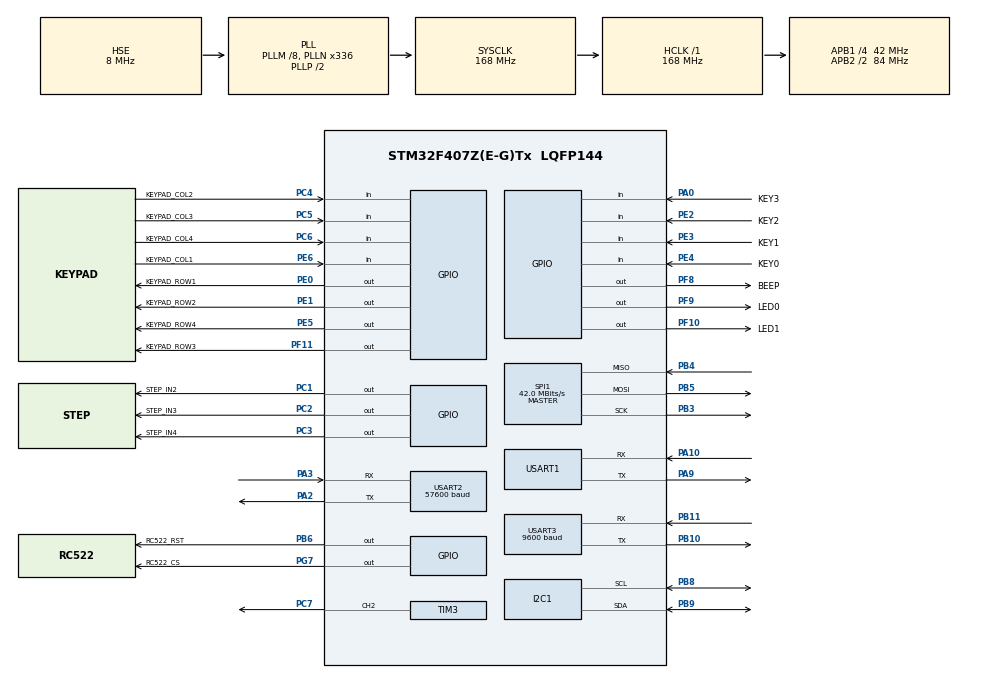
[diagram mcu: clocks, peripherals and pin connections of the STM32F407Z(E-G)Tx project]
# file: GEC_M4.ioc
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FREERTOS.Tasks01=defaultTask,24,128,StartDefaultTask,Default,NULL,Dynamic,NULL,NULL
Mcu.Family=STM32F4
Mcu.Name=STM32F407Z(E-G)Tx
Mcu.Package=LQFP144
NVIC.PriorityGroup=NVIC_PRIORITYGROUP_4
NVIC.TIM1_UP_TIM10_IRQn=true\:0\:0\:false\:false\:true\:false\:false\:true
NVIC.TimeBase=TIM1_UP_TIM10_IRQn
NVIC.TimeBaseIP=TIM1
NVIC.USART1_IRQn=true\:5\:0\:true\:false\:true\:true\:true\:true
NVIC.USART2_IRQn=true\:5\:0\:true\:false\:true\:true\:true\:true
NVIC.USART3_IRQn=true\:5\:0\:true\:false\:true\:true\:true\:true
PA0-WKUP.GPIO_Label=KEY3
PA0-WKUP.GPIO_Pull=GPIO_NOPULL
PA0-WKUP.Signal=GPIO_Input
PA10.Mode=Asynchronous
PA10.Signal=USART1_RX
PA13.Mode=Serial_Wire
PA13.Signal=SYS_JTMS-SWDIO
PA14.Mode=Serial_Wire
PA14.Signal=SYS_JTCK-SWCLK
PA2.Mode=Asynchronous
PA2.Signal=USART2_TX
PA3.Mode=Asynchronous
PA3.Signal=USART2_RX
PA9.Mode=Asynchronous
PA9.Signal=USART1_TX
PB10.Mode=Asynchronous
PB10.Signal=USART3_TX
PB11.Mode=Asynchronous
PB11.Signal=USART3_RX
PC7.Signal=S_TIM3_CH2
PF11.GPIO_Label=KEYPAD_ROW3
PF11.Signal=GPIO_Output
PG7.GPIO_Label=RC522_CS
PG7.Signal=GPIO_Output
PB3.Mode=Full_Duplex_Master
PB3.Signal=SPI1_SCK
PB4.Mode=Full_Duplex_Master
PB4.Signal=SPI1_MISO
PB5.Mode=Full_Duplex_Master
PB5.Signal=SPI1_MOSI
PB6.GPIO_Label=RC522_RST
PB6.Signal=GPIO_Output
PB8.Mode=I2C
PB8.Signal=I2C1_SCL
PB9.Mode=I2C
PB9.Signal=I2C1_SDA
PC1.GPIO_Label=STEP_IN2
PC1.GPIO_Speed=GPIO_SPEED_FREQ_VERY_HIGH
PC1.Signal=GPIO_Output
PC14-OSC32_IN.Mode=LSE-External-Oscillator
PC14-OSC32_IN.Signal=RCC_OSC32_IN
PC15-OSC32_OUT.Mode=LSE-External-Oscillator
PC15-OSC32_OUT.Signal=RCC_OSC32_OUT
PC2.GPIO_Label=STEP_IN3
PC2.GPIO_Speed=GPIO_SPEED_FREQ_VERY_HIGH
PC2.Signal=GPIO_Output
PC3.GPIO_Label=STEP_IN4
PC3.GPIO_Speed=GPIO_SPEED_FREQ_VERY_HIGH
PC3.Signal=GPIO_Output
PC4.GPIO_Label=KEYPAD_COL2
PC4.GPIO_Pull=GPIO_PULLUP
PC4.Signal=GPIO_Input
PC5.GPIO_Label=KEYPAD_COL3
PC5.GPIO_Pull=GPIO_PULLUP
PC5.Signal=GPIO_Input
PC6.GPIO_Label=KEYPAD_COL4
PC6.GPIO_Pull=GPIO_PULLUP
PC6.Signal=GPIO_Input
PE0.GPIO_Label=KEYPAD_ROW1
PE0.GPIO_Speed=GPIO_SPEED_FREQ_VERY_HIGH
PE0.Signal=GPIO_Output
PE1.GPIO_Label=KEYPAD_ROW2
PE1.GPIO_Speed=GPIO_SPEED_FREQ_VERY_HIGH
PE1.Signal=GPIO_Output
PE2.GPIO_Label=KEY2
PE2.GPIO_Pull=GPIO_NOPULL
PE2.Signal=GPIO_Input
PE3.GPIO_Label=KEY1
PE3.GPIO_Pull=GPIO_NOPULL
PE3.Signal=GPIO_Input
PE4.GPIO_Label=KEY0
PE4.GPIO_Pull=GPIO_NOPULL
PE4.Signal=GPIO_Input
PE5.GPIO_Label=KEYPAD_ROW4
PE5.GPIO_Speed=GPIO_SPEED_FREQ_VERY_HIGH
PE5.Signal=GPIO_Output
PE6.GPIO_Label=KEYPAD_COL1
PE6.GPIO_Pull=GPIO_PULLUP
PE6.Signal=GPIO_Input
PF10.GPIO_Label=LED1
PF10.GPIO_Speed=GPIO_SPEED_FREQ_VERY_HIGH
PF10.Signal=GPIO_Output
PF8.GPIO_Label=BEEP
PF8.GPIO_Speed=GPIO_SPEED_FREQ_VERY_HIGH
PF8.Signal=GPIO_Output
PF9.GPIO_Label=LED0
PF9.GPIO_Speed=GPIO_SPEED_FREQ_VERY_HIGH
PF9.Signal=GPIO_Output
PH0-OSC_IN.Mode=HSE-External-Oscillator
PH0-OSC_IN.Signal=RCC_OSC_IN
PH1-OSC_OUT.Mode=HSE-External-Oscillator
PH1-OSC_OUT.Signal=RCC_OSC_OUT
ProjectManager.HeapSize=0x200
ProjectManager.StackSize=0x400
ProjectManager.TargetToolchain=MDK-ARM V5.27
RCC.48MHZClocksFreq_Value=84000000
RCC.AHBFreq_Value=168000000
RCC.APB1CLKDivider=RCC_HCLK_DIV4
RCC.APB1Freq_Value=42000000
RCC.APB1TimFreq_Value=84000000
RCC.APB2CLKDivider=RCC_HCLK_DIV2
RCC.APB2Freq_Value=84000000
RCC.APB2TimFreq_Value=168000000
RCC.CortexFreq_Value=168000000
RCC.HCLKFreq_Value=168000000
RCC.HSE_VALUE=8000000
RCC.HSI_VALUE=16000000
RCC.PLLM=8
RCC.PLLN=336
RCC.PLLSourceVirtual=RCC_PLLSOURCE_HSE
RCC.SYSCLKFreq_VALUE=168000000
RCC.SYSCLKSource=RCC_SYSCLKSOURCE_PLLCLK
RCC.VCOOutputFreq_Value=336000000
SH.S_TIM3_CH2.0=TIM3_CH2,PWM Generation2 CH2
SPI1.CalculateBaudRate=42.0 MBits/s
SPI1.Direction=SPI_DIRECTION_2LINES
SPI1.Mode=SPI_MODE_MASTER
SPI1.VirtualType=VM_MASTER
TIM3.Channel-PWM\ Generation2\ CH2=TIM_CHANNEL_2
TIM3.Period=19999
TIM3.Prescaler=83
USART1.VirtualMode=VM_ASYNC
USART2.BaudRate=57600
USART2.VirtualMode=VM_ASYNC
USART3.BaudRate=9600
USART3.VirtualMode=VM_ASYNC
VP_FREERTOS_VS_CMSIS_V2.Mode=CMSIS_V2
VP_SYS_VS_tim1.Mode=TIM1
VP_TIM3_VS_ClockSourceINT.Mode=Internal
board=custom

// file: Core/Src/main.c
/* USER CODE BEGIN Header */
/**
  ******************************************************************************
  * @file           : main.c
  * @brief          : Main program body
  ******************************************************************************
  * @attention
  *
  * <h2><center>&copy; Copyright (c) 2026 STMicroelectronics.
  * All rights reserved.</center></h2>
  *
  * This software component is licensed by ST under Ultimate Liberty license
  * SLA0044, the "License"; You may not use this file except in compliance with
  * the License. You may obtain a copy of the License at:
  *                             www.st.com/SLA0044
  *
  ******************************************************************************
  */
/* USER CODE END Header */
#include "main.h"
#include "cmsis_os.h"
#include "i2c.h"
#include "spi.h"
#include "tim.h"
#include "usart.h"
#include "gpio.h"

/* USER CODE BEGIN Includes */
#include "app_auth.h"
/* USER CODE END Includes */

void SystemClock_Config(void);
void MX_FREERTOS_Init(void);

int main(void)
{

  /* MCU Configuration--------------------------------------------------------*/

  /* Reset of all peripherals, Initializes the Flash interface and the Systick. */
  HAL_Init();

  /* Configure the system clock */
  SystemClock_Config();

  /* Initialize all configured peripherals */
  MX_GPIO_Init();            /* 通用 GPIO：4x4 矩阵键盘行/列引脚、LED 等 */
  MX_USART1_UART_Init();     /* USART1(PA9/10)：PC 通信，接板载 CH340 虚拟 COM，收 PC 下发的认证结果 */
  MX_USART2_UART_Init();     /* USART2(PA2/3)：ZW111 指纹模块(57600) */
  MX_USART3_UART_Init();     /* USART3(PB10/11)：JQ8900 语音播报模块 */
  MX_I2C1_Init();            /* I2C1(PB8/PB9)：OLED 显示屏（硬件 I2C，接板载 P3 排针） */
  MX_SPI1_Init();            /* SPI1(PB3/4/5)：RC522 刷卡模块，SCK/MOSI/MISO 经 U13 NRF 座引出；CS=PG7(U13 CSN 孔)、RST=PB6(P8 座 pin13) */
  MX_TIM3_Init();            /* TIM3_CH2(PC7)：舵机 PWM（50Hz，模拟开锁；PC7 从 P8 摄像头排母座 pin9 引出） */
  /* USER CODE BEGIN 2 */
  APP_Auth_Init();   /* 初始化舵机/OLED/RC522 并创建刷卡任务（调度器启动前调用） */
  /* USER CODE END 2 */

  /* Init scheduler */
  osKernelInitialize();  /* Call init function for freertos objects (in freertos.c) */
  MX_FREERTOS_Init();
  /* Start scheduler */
  osKernelStart();

  /* We should never get here as control is now taken by the scheduler */
  /* Infinite loop */
  while (1)
  {

  }
}

void SystemClock_Config(void)
{
  RCC_OscInitTypeDef RCC_OscInitStruct = {0};
  RCC_ClkInitTypeDef RCC_ClkInitStruct = {0};

  /** Configure the main internal regulator output voltage
  */
  __HAL_RCC_PWR_CLK_ENABLE();
  __HAL_PWR_VOLTAGESCALING_CONFIG(PWR_REGULATOR_VOLTAGE_SCALE1);
  /** Initializes the RCC Oscillators according to the specified parameters
  * in the RCC_OscInitTypeDef structure.
  */
  RCC_OscInitStruct.OscillatorType = RCC_OSCILLATORTYPE_HSE;
  RCC_OscInitStruct.HSEState = RCC_HSE_ON;
  RCC_OscInitStruct.PLL.PLLState = RCC_PLL_ON;
  RCC_OscInitStruct.PLL.PLLSource = RCC_PLLSOURCE_HSE;
  RCC_OscInitStruct.PLL.PLLM = 8;
  RCC_OscInitStruct.PLL.PLLN = 336;
  RCC_OscInitStruct.PLL.PLLP = RCC_PLLP_DIV2;
  RCC_OscInitStruct.PLL.PLLQ = 4;
  if (HAL_RCC_OscConfig(&RCC_OscInitStruct) != HAL_OK)
  {
    Error_Handler();
  }
  /** Initializes the CPU, AHB and APB buses clocks
  */
  RCC_ClkInitStruct.ClockType = RCC_CLOCKTYPE_HCLK|RCC_CLOCKTYPE_SYSCLK
                              |RCC_CLOCKTYPE_PCLK1|RCC_CLOCKTYPE_PCLK2;
  RCC_ClkInitStruct.SYSCLKSource = RCC_SYSCLKSOURCE_PLLCLK;
  RCC_ClkInitStruct.AHBCLKDivider = RCC_SYSCLK_DIV1;
  RCC_ClkInitStruct.APB1CLKDivider = RCC_HCLK_DIV4;
  RCC_ClkInitStruct.APB2CLKDivider = RCC_HCLK_DIV2;

  if (HAL_RCC_ClockConfig(&RCC_ClkInitStruct, FLASH_LATENCY_5) != HAL_OK)
  {
    Error_Handler();
  }
}

 /**
  * @brief  Period elapsed callback in non blocking mode
  * @note   This function is called  when TIM1 interrupt took place, inside
  * HAL_TIM_IRQHandler(). It makes a direct call to HAL_IncTick() to increment
  * a global variable "uwTick" used as application time base.
  * @param  htim : TIM handle
  * @retval None
  */
void HAL_TIM_PeriodElapsedCallback(TIM_HandleTypeDef *htim)
{
  if (htim->Instance == TIM1) {
    HAL_IncTick();
  }
}

void Error_Handler(void)
{
  __disable_irq();
  while (1)
  {
  }
}

/************************ (C) COPYRIGHT STMicroelectronics *****END OF FILE****/

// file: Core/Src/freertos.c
/* USER CODE BEGIN Header */
/**
  ******************************************************************************
  * File Name          : freertos.c
  * Description        : Code for freertos applications
  ******************************************************************************
  * @attention
  *
  * <h2><center>&copy; Copyright (c) 2026 STMicroelectronics.
  * All rights reserved.</center></h2>
  *
  * This software component is licensed by ST under Ultimate Liberty license
  * SLA0044, the "License"; You may not use this file except in compliance with
  * the License. You may obtain a copy of the License at:
  *                             www.st.com/SLA0044
  *
  ******************************************************************************
  */
/* USER CODE END Header */

#include "FreeRTOS.h"
#include "task.h"
#include "main.h"
#include "cmsis_os.h"

/* Definitions for defaultTask */
osThreadId_t defaultTaskHandle;
const osThreadAttr_t defaultTask_attributes = {
  .name = "defaultTask",
  .stack_size = 128 * 4,
  .priority = (osPriority_t) osPriorityNormal,
};

void StartDefaultTask(void *argument);

void MX_FREERTOS_Init(void); /* (MISRA C 2004 rule 8.1) */

void MX_FREERTOS_Init(void) {

  /* Create the thread(s) */
  /* creation of defaultTask */
  defaultTaskHandle = osThreadNew(StartDefaultTask, NULL, &defaultTask_attributes);

}

void StartDefaultTask(void *argument)
{
  for(;;)
  {
    osDelay(1);
  }
}

/* USER CODE BEGIN Application */
void vApplicationIdleHook(void)
{
  __WFI();      /* 没活干就睡，任何中断都能唤醒 */
}
/* USER CODE END Application */

/************************ (C) COPYRIGHT STMicroelectronics *****END OF FILE****/
